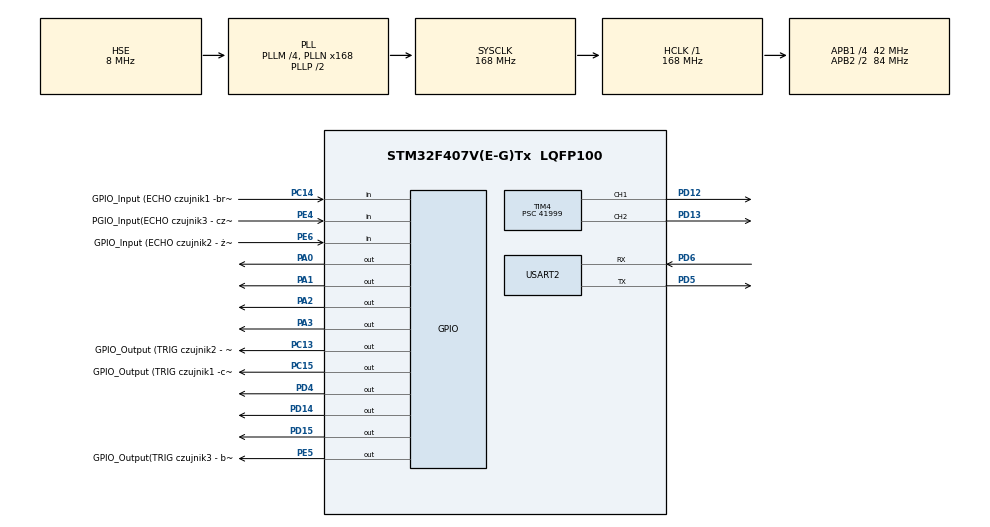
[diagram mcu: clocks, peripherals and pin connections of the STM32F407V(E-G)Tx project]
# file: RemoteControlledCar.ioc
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Mcu.Family=STM32F4
Mcu.Name=STM32F407V(E-G)Tx
Mcu.Package=LQFP100
NVIC.PriorityGroup=NVIC_PRIORITYGROUP_4
NVIC.TIM1_UP_TIM10_IRQn=true\:0\:0\:false\:false\:true\:false\:true
NVIC.TimeBase=TIM1_UP_TIM10_IRQn
NVIC.TimeBaseIP=TIM1
PA0-WKUP.Signal=GPIO_Output
PA1.Signal=GPIO_Output
PA2.Signal=GPIO_Output
PA3.Signal=GPIO_Output
PC13-ANTI_TAMP.GPIO_Label=GPIO_Output (TRIG czujnik2 - pomara\u0144czowy)
PC13-ANTI_TAMP.Signal=GPIO_Output
PC14-OSC32_IN.GPIO_Label=GPIO_Input (ECHO czujnik1 -br\u0105zowy
PC14-OSC32_IN.Signal=GPIO_Input
PC15-OSC32_OUT.GPIO_Label=GPIO_Output (TRIG czujnik1 -czerwony
PC15-OSC32_OUT.Signal=GPIO_Output
PD12.Signal=S_TIM4_CH1
PD13.Signal=S_TIM4_CH2
PD14.Signal=GPIO_Output
PD15.Signal=GPIO_Output
PD4.PinState=GPIO_PIN_SET
PD4.Signal=GPIO_Output
PD5.Mode=Asynchronous
PD5.Signal=USART2_TX
PD6.Mode=Asynchronous
PD6.Signal=USART2_RX
PE4.GPIO_Label=PGIO_Input(ECHO czujnik3 - czarny)
PE4.Signal=GPIO_Input
PE5.GPIO_Label=GPIO_Output(TRIG czujnik3 - bia\u0142y
PE5.Signal=GPIO_Output
PE6.GPIO_Label=GPIO_Input (ECHO czujnik2 - \u017C\u00F3\u0142ty)
PE6.Signal=GPIO_Input
PH0-OSC_IN.Mode=HSE-External-Oscillator
PH0-OSC_IN.Signal=RCC_OSC_IN
PH1-OSC_OUT.Mode=HSE-External-Oscillator
PH1-OSC_OUT.Signal=RCC_OSC_OUT
ProjectManager.HeapSize=0x200
ProjectManager.StackSize=0x400
ProjectManager.TargetToolchain=STM32CubeIDE
RCC.48MHZClocksFreq_Value=84000000
RCC.AHBFreq_Value=168000000
RCC.APB1CLKDivider=RCC_HCLK_DIV4
RCC.APB1Freq_Value=42000000
RCC.APB1TimFreq_Value=84000000
RCC.APB2CLKDivider=RCC_HCLK_DIV2
RCC.APB2Freq_Value=84000000
RCC.APB2TimFreq_Value=168000000
RCC.CortexFreq_Value=168000000
RCC.HCLKFreq_Value=168000000
RCC.HSE_VALUE=8000000
RCC.HSI_VALUE=16000000
RCC.LSE_VALUE=32768
RCC.PLLM=4
RCC.PLLN=168
RCC.PLLSourceVirtual=RCC_PLLSOURCE_HSE
RCC.SYSCLKFreq_VALUE=168000000
RCC.SYSCLKSource=RCC_SYSCLKSOURCE_PLLCLK
RCC.VCOOutputFreq_Value=336000000
SH.S_TIM4_CH1.0=TIM4_CH1,PWM Generation1 CH1
SH.S_TIM4_CH2.0=TIM4_CH2,PWM Generation2 CH2
TIM4.Channel-PWM\ Generation1\ CH1=TIM_CHANNEL_1
TIM4.Channel-PWM\ Generation2\ CH2=TIM_CHANNEL_2
TIM4.Period=1999
TIM4.Prescaler=41999
TIM4.Pulse-PWM\ Generation1\ CH1=1999
TIM4.Pulse-PWM\ Generation2\ CH2=1999
USART2.VirtualMode=VM_ASYNC
VP_SYS_VS_tim1.Mode=TIM1
VP_TIM4_VS_ClockSourceINT.Mode=Internal
board=custom

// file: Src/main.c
/* USER CODE BEGIN Header */
/**
  ******************************************************************************
  * @file           : main.c
  * @brief          : Main program body
  ******************************************************************************
  * @attention
  *
  * <h2><center>&copy; Copyright (c) 2020 STMicroelectronics.
  * All rights reserved.</center></h2>
  *
  * This software component is licensed by ST under BSD 3-Clause license,
  * the "License"; You may not use this file except in compliance with the
  * License. You may obtain a copy of the License at:
  *                        opensource.org/licenses/BSD-3-Clause
  *
  ******************************************************************************
  */
/* USER CODE END Header */

#include "main.h"

/* USER CODE BEGIN Includes */
#include "dwt_stm32_delay.h"
#include "ESP_INIT.h"
#include "ENG_CONTROL.h"
#include "UDS_INIT.h"
//#include "UDS_INIT.h"
/* USER CODE END Includes */

TIM_HandleTypeDef htim4;

UART_HandleTypeDef huart2;

void SystemClock_Config(void);
static void MX_GPIO_Init(void);
static void MX_TIM4_Init(void);
static void MX_USART2_UART_Init(void);

int main(void)
{

  /* MCU Configuration--------------------------------------------------------*/

  /* Reset of all peripherals, Initializes the Flash interface and the Systick. */
  HAL_Init();

  /* Configure the system clock */
  SystemClock_Config();

  /* Initialize all configured peripherals */
  MX_GPIO_Init();
  MX_TIM4_Init();
  MX_USART2_UART_Init();
  /* USER CODE BEGIN 2 */
  	  	  	  	  	  	  	  	  	  	  	  /* TIM 4 ON */
  HAL_TIM_Base_Start_IT(&htim4);
  HAL_TIM_PWM_Start(&htim4, TIM_CHANNEL_1);
  HAL_TIM_PWM_Start(&htim4, TIM_CHANNEL_2);
  	  	  	  	  	  	  	  	  	  	  	  /* DELAY DWT */
  DWT_Delay_Init();

  ESP_Init();
  /* USER CODE END 2 */

  /* Infinite loop */
  /* USER CODE BEGIN WHILE */

  	  	  	  	  	  	  	  	  	  	  	  	  /* TESTY NAD WIFI -> DLACZEGO NIE DZIA�?A?! PART 2 */

  while(1)
  {
    /* USER CODE END WHILE */

    /* USER CODE BEGIN 3 */

		  CM_init();
  }
  /* USER CODE END 3 */
}

void SystemClock_Config(void)
{
  RCC_OscInitTypeDef RCC_OscInitStruct = {0};
  RCC_ClkInitTypeDef RCC_ClkInitStruct = {0};

  /** Configure the main internal regulator output voltage
  */
  __HAL_RCC_PWR_CLK_ENABLE();
  __HAL_PWR_VOLTAGESCALING_CONFIG(PWR_REGULATOR_VOLTAGE_SCALE1);
  /** Initializes the CPU, AHB and APB busses clocks
  */
  RCC_OscInitStruct.OscillatorType = RCC_OSCILLATORTYPE_HSE;
  RCC_OscInitStruct.HSEState = RCC_HSE_ON;
  RCC_OscInitStruct.PLL.PLLState = RCC_PLL_ON;
  RCC_OscInitStruct.PLL.PLLSource = RCC_PLLSOURCE_HSE;
  RCC_OscInitStruct.PLL.PLLM = 4;
  RCC_OscInitStruct.PLL.PLLN = 168;
  RCC_OscInitStruct.PLL.PLLP = RCC_PLLP_DIV2;
  RCC_OscInitStruct.PLL.PLLQ = 4;
  if (HAL_RCC_OscConfig(&RCC_OscInitStruct) != HAL_OK)
  {
    Error_Handler();
  }
  /** Initializes the CPU, AHB and APB busses clocks
  */
  RCC_ClkInitStruct.ClockType = RCC_CLOCKTYPE_HCLK|RCC_CLOCKTYPE_SYSCLK
                              |RCC_CLOCKTYPE_PCLK1|RCC_CLOCKTYPE_PCLK2;
  RCC_ClkInitStruct.SYSCLKSource = RCC_SYSCLKSOURCE_PLLCLK;
  RCC_ClkInitStruct.AHBCLKDivider = RCC_SYSCLK_DIV1;
  RCC_ClkInitStruct.APB1CLKDivider = RCC_HCLK_DIV4;
  RCC_ClkInitStruct.APB2CLKDivider = RCC_HCLK_DIV2;

  if (HAL_RCC_ClockConfig(&RCC_ClkInitStruct, FLASH_LATENCY_5) != HAL_OK)
  {
    Error_Handler();
  }
}

static void MX_TIM4_Init(void)
{

  TIM_ClockConfigTypeDef sClockSourceConfig = {0};
  TIM_MasterConfigTypeDef sMasterConfig = {0};
  TIM_OC_InitTypeDef sConfigOC = {0};

  htim4.Instance = TIM4;
  htim4.Init.Prescaler = 41;
  htim4.Init.CounterMode = TIM_COUNTERMODE_UP;
  htim4.Init.Period = 1999;
  htim4.Init.ClockDivision = TIM_CLOCKDIVISION_DIV1;
  htim4.Init.AutoReloadPreload = TIM_AUTORELOAD_PRELOAD_DISABLE;
  if (HAL_TIM_Base_Init(&htim4) != HAL_OK)
  {
    Error_Handler();
  }
  sClockSourceConfig.ClockSource = TIM_CLOCKSOURCE_INTERNAL;
  if (HAL_TIM_ConfigClockSource(&htim4, &sClockSourceConfig) != HAL_OK)
  {
    Error_Handler();
  }
  if (HAL_TIM_PWM_Init(&htim4) != HAL_OK)
  {
    Error_Handler();
  }
  sMasterConfig.MasterOutputTrigger = TIM_TRGO_RESET;
  sMasterConfig.MasterSlaveMode = TIM_MASTERSLAVEMODE_DISABLE;
  if (HAL_TIMEx_MasterConfigSynchronization(&htim4, &sMasterConfig) != HAL_OK)
  {
    Error_Handler();
  }
  sConfigOC.OCMode = TIM_OCMODE_PWM1;
  sConfigOC.Pulse = 1999;
  sConfigOC.OCPolarity = TIM_OCPOLARITY_HIGH;
  sConfigOC.OCFastMode = TIM_OCFAST_DISABLE;
  if (HAL_TIM_PWM_ConfigChannel(&htim4, &sConfigOC, TIM_CHANNEL_1) != HAL_OK)
  {
    Error_Handler();
  }
  if (HAL_TIM_PWM_ConfigChannel(&htim4, &sConfigOC, TIM_CHANNEL_2) != HAL_OK)
  {
    Error_Handler();
  }
  HAL_TIM_MspPostInit(&htim4);

}

static void MX_USART2_UART_Init(void)
{

  huart2.Instance = USART2;
  huart2.Init.BaudRate = 115200;
  huart2.Init.WordLength = UART_WORDLENGTH_8B;
  huart2.Init.StopBits = UART_STOPBITS_1;
  huart2.Init.Parity = UART_PARITY_NONE;
  huart2.Init.Mode = UART_MODE_TX_RX;
  huart2.Init.HwFlowCtl = UART_HWCONTROL_NONE;
  huart2.Init.OverSampling = UART_OVERSAMPLING_16;
  if (HAL_UART_Init(&huart2) != HAL_OK)
  {
    Error_Handler();
  }

}

static void MX_GPIO_Init(void)
{
  GPIO_InitTypeDef GPIO_InitStruct = {0};

  /* GPIO Ports Clock Enable */
  __HAL_RCC_GPIOE_CLK_ENABLE();
  __HAL_RCC_GPIOC_CLK_ENABLE();
  __HAL_RCC_GPIOH_CLK_ENABLE();
  __HAL_RCC_GPIOA_CLK_ENABLE();
  __HAL_RCC_GPIOD_CLK_ENABLE();

  /*Configure GPIO pin Output Level */
  HAL_GPIO_WritePin(GPIO_Output_TRIG_czujnik3___bia_y_GPIO_Port, GPIO_Output_TRIG_czujnik3___bia_y_Pin, GPIO_PIN_RESET);

  /*Configure GPIO pin Output Level */
  HAL_GPIO_WritePin(GPIOC, GPIO_Output_Pin|GPIO_Output__TRIG_czujnik1__czerwony_Pin, GPIO_PIN_RESET);

  /*Configure GPIO pin Output Level */
  HAL_GPIO_WritePin(GPIOA, GPIO_PIN_0|GPIO_PIN_1|GPIO_PIN_2|GPIO_PIN_3, GPIO_PIN_RESET);

  /*Configure GPIO pin Output Level */
  HAL_GPIO_WritePin(GPIOD, GPIO_PIN_14|GPIO_PIN_15, GPIO_PIN_RESET);

  /*Configure GPIO pin Output Level */
  HAL_GPIO_WritePin(GPIOD, GPIO_PIN_4, GPIO_PIN_SET);

  /*Configure GPIO pins : PGIO_Input_Pin GPIO_Input_Pin */
  GPIO_InitStruct.Pin = PGIO_Input_Pin|GPIO_Input_Pin;
  GPIO_InitStruct.Mode = GPIO_MODE_INPUT;
  GPIO_InitStruct.Pull = GPIO_NOPULL;
  HAL_GPIO_Init(GPIOE, &GPIO_InitStruct);

  /*Configure GPIO pin : GPIO_Output_TRIG_czujnik3___bia_y_Pin */
  GPIO_InitStruct.Pin = GPIO_Output_TRIG_czujnik3___bia_y_Pin;
  GPIO_InitStruct.Mode = GPIO_MODE_OUTPUT_PP;
  GPIO_InitStruct.Pull = GPIO_NOPULL;
  GPIO_InitStruct.Speed = GPIO_SPEED_FREQ_LOW;
  HAL_GPIO_Init(GPIO_Output_TRIG_czujnik3___bia_y_GPIO_Port, &GPIO_InitStruct);

  /*Configure GPIO pins : GPIO_Output_Pin GPIO_Output__TRIG_czujnik1__czerwony_Pin */
  GPIO_InitStruct.Pin = GPIO_Output_Pin|GPIO_Output__TRIG_czujnik1__czerwony_Pin;
  GPIO_InitStruct.Mode = GPIO_MODE_OUTPUT_PP;
  GPIO_InitStruct.Pull = GPIO_NOPULL;
  GPIO_InitStruct.Speed = GPIO_SPEED_FREQ_LOW;
  HAL_GPIO_Init(GPIOC, &GPIO_InitStruct);

  /*Configure GPIO pin : GPIO_Input__ECHO_czujnik1__br_zowy_Pin */
  GPIO_InitStruct.Pin = GPIO_Input__ECHO_czujnik1__br_zowy_Pin;
  GPIO_InitStruct.Mode = GPIO_MODE_INPUT;
  GPIO_InitStruct.Pull = GPIO_NOPULL;
  HAL_GPIO_Init(GPIO_Input__ECHO_czujnik1__br_zowy_GPIO_Port, &GPIO_InitStruct);

  /*Configure GPIO pins : PA0 PA1 PA2 PA3 */
  GPIO_InitStruct.Pin = GPIO_PIN_0|GPIO_PIN_1|GPIO_PIN_2|GPIO_PIN_3;
  GPIO_InitStruct.Mode = GPIO_MODE_OUTPUT_PP;
  GPIO_InitStruct.Pull = GPIO_NOPULL;
  GPIO_InitStruct.Speed = GPIO_SPEED_FREQ_LOW;
  HAL_GPIO_Init(GPIOA, &GPIO_InitStruct);

  /*Configure GPIO pins : PD14 PD15 PD4 */
  GPIO_InitStruct.Pin = GPIO_PIN_14|GPIO_PIN_15|GPIO_PIN_4;
  GPIO_InitStruct.Mode = GPIO_MODE_OUTPUT_PP;
  GPIO_InitStruct.Pull = GPIO_NOPULL;
  GPIO_InitStruct.Speed = GPIO_SPEED_FREQ_LOW;
  HAL_GPIO_Init(GPIOD, &GPIO_InitStruct);

}

 /**
  * @brief  Period elapsed callback in non blocking mode
  * @note   This function is called  when TIM1 interrupt took place, inside
  * HAL_TIM_IRQHandler(). It makes a direct call to HAL_IncTick() to increment
  * a global variable "uwTick" used as application time base.
  * @param  htim : TIM handle
  * @retval None
  */
void HAL_TIM_PeriodElapsedCallback(TIM_HandleTypeDef *htim)
{
  if (htim->Instance == TIM1) {
    HAL_IncTick();
  }
}

void Error_Handler(void)
{
}

/************************ (C) COPYRIGHT STMicroelectronics *****END OF FILE****/
